VERSION ""

NS_ :

BS_:

BU_: Wheel23

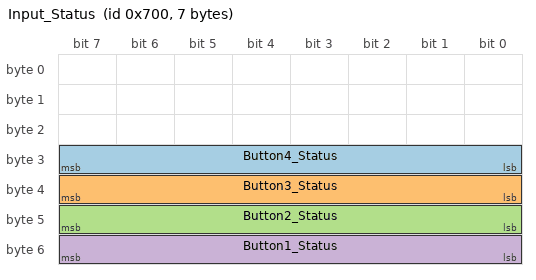
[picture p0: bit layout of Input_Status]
BO_ 1792 Input_Status: 7 Wheel23
 SG_ Button4_Status : 24|8@1- (1,0) [0|0] "" Vector__XXX
 SG_ Button3_Status : 32|8@1- (1,0) [0|0] "" Vector__XXX
 SG_ Button2_Status : 40|8@1- (1,0) [0|0] "" Vector__XXX
 SG_ Button1_Status : 48|8@1- (1,0) [0|0] "" Vector__XXX
